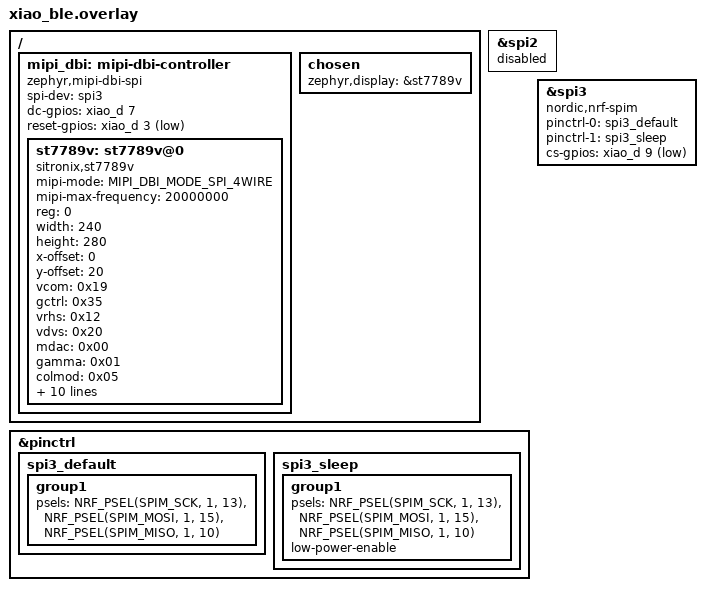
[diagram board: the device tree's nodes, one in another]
// Waveshare 1.69" round LCD (ST7789V, 240x280) on XIAO nRF52840.
// Zephyr 4.1 MIPI-DBI SPI structure (old cmd-data-gpios style removed).
// CS=D9(P1.14) DC=D7(P1.12) RST=D3(P0.29)
// SPI3 reuses the XIAO SPI header pins; disable SPI2 to free them.

&spi2 { status = "disabled"; };

&pinctrl {
    spi3_default: spi3_default {
        group1 {
            psels = <NRF_PSEL(SPIM_SCK,  1, 13)>,
                    <NRF_PSEL(SPIM_MOSI, 1, 15)>,
                    <NRF_PSEL(SPIM_MISO, 1, 10)>;
        };
    };
    spi3_sleep: spi3_sleep {
        group1 {
            psels = <NRF_PSEL(SPIM_SCK,  1, 13)>,
                    <NRF_PSEL(SPIM_MOSI, 1, 15)>,
                    <NRF_PSEL(SPIM_MISO, 1, 10)>;
            low-power-enable;
        };
    };
};

&spi3 {
    compatible = "nordic,nrf-spim";
    status = "okay";
    pinctrl-0 = <&spi3_default>;
    pinctrl-1 = <&spi3_sleep>;
    pinctrl-names = "default", "sleep";
    cs-gpios = <&xiao_d 9 GPIO_ACTIVE_LOW>;
};

/ {
    mipi_dbi: mipi-dbi-controller {
        compatible = "zephyr,mipi-dbi-spi";
        spi-dev = <&spi3>;
        dc-gpios    = <&xiao_d 7 GPIO_ACTIVE_HIGH>;
        reset-gpios = <&xiao_d 3 GPIO_ACTIVE_LOW>;
        #address-cells = <1>;
        #size-cells = <0>;

        st7789v: st7789v@0 {
            compatible = "sitronix,st7789v";
            mipi-mode = "MIPI_DBI_MODE_SPI_4WIRE";
            mipi-max-frequency = <20000000>;
            reg = <0>;
            width  = <240>;
            height = <280>;
            x-offset = <0>;
            y-offset = <20>;
            vcom        = <0x19>;
            gctrl       = <0x35>;
            vrhs        = <0x12>;
            vdvs        = <0x20>;
            mdac        = <0x00>;
            gamma       = <0x01>;
            colmod      = <0x05>;
            lcm         = <0x2c>;
            porch-param   = [ 0c 0c 00 33 33 ];
            cmd2en-param  = [ 5a 69 02 01 ];
            pwctrl1-param = [ a4 a1 ];
            pvgam-param   = [ D0 04 0D 11 13 2B 3F 54 4C 18 0D 0B 1F 23 ];
            nvgam-param   = [ D0 04 0C 11 13 2C 3F 44 51 2F 1F 1F 20 23 ];
            ram-param     = [ 00 F0 ];
            rgb-param     = [ CD 08 14 ];
        };
    };

    chosen {
        zephyr,display = &st7789v;
    };
};
